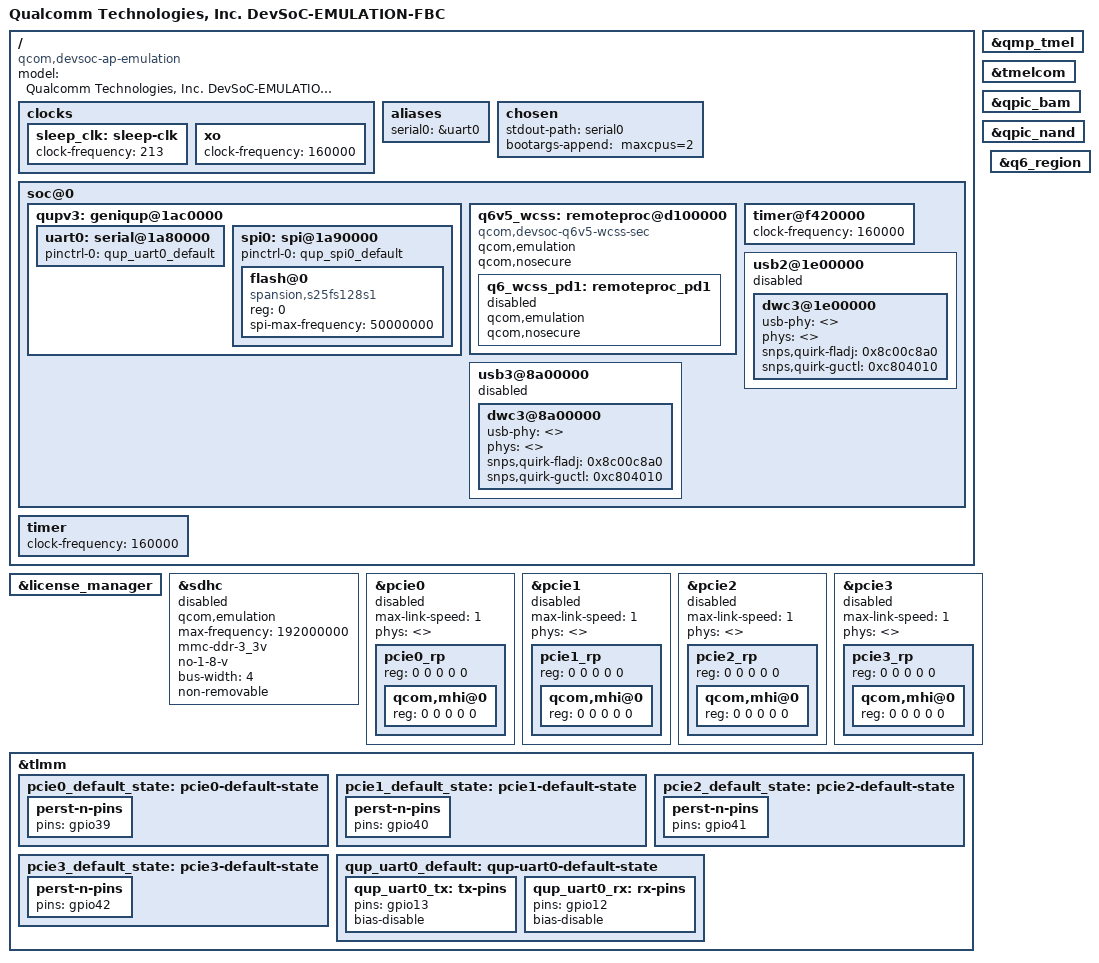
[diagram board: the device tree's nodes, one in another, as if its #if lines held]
// SPDX-License-Identifier: (GPL-2.0+ OR BSD-3-Clause)
/*
 * Dev SoC Emulation board device tree source
 *
 * Copyright (c) 2020-2021 The Linux Foundation. All rights reserved.
 * Copyright (c) 2022-2023 Qualcomm Innovation Center, Inc. All rights reserved.
 */

/dts-v1/;

#include "devsoc.dtsi"

/ {
	model = "Qualcomm Technologies, Inc. DevSoC-EMULATION-FBC";
	compatible = "qcom,devsoc-ap-emulation", "qcom,devsoc";

	/*Timer freq for rumi = timer freq / 150*/
	clocks {
		sleep_clk: sleep-clk {
			clock-frequency = <213>;
		};

		xo: xo {
			clock-frequency = <160000>;
		};
	};

	aliases {
		serial0 = &uart0;
	};

	chosen {
		stdout-path = "serial0";
		bootargs-append = " maxcpus=2";
	};

	soc@0 {
		qupv3: geniqup@1ac0000 {
			status = "okay";

			uart0: serial@1a80000 {
				pinctrl-0 = <&qup_uart0_default>;
				pinctrl-names = "default";
				status = "okay";
			};

			spi0: spi@1a90000 {
				pinctrl-0 = <&qup_spi0_default>;
				pinctrl-names = "default";
				status = "okay";

				flash@0 {
					compatible = "spansion,s25fs128s1", "jedec,spi-nor";
					#address-cells = <1>;
					#size-cells = <1>;
					reg = <0>;
					spi-max-frequency = <50000000>;
				};
			};
		};

		q6v5_wcss: remoteproc@d100000 {
			compatible = "qcom,devsoc-q6v5-wcss-sec";
			status = "okay";

#ifdef __QCOM_NON_SECURE_PIL__
			qcom,emulation;
			qcom,nosecure;
#endif
			q6_wcss_pd1: remoteproc_pd1 {
				status = "disabled";
#ifdef __QCOM_NON_SECURE_PIL__
				qcom,emulation;
				qcom,nosecure;
#endif
			};
		};

		/* Timer freq for rumi = timer freq / 150 */
		timer@f420000 {
			clock-frequency = <160000>;
		};

		usb2@1e00000 {
			status = "disabled";

			dwc3@1e00000 {
				usb-phy = <>;
				phys = <>;
				phy-names = "";
				snps,quirk-fladj = <0x8c00c8a0>;
				snps,quirk-guctl = <0xc804010>;
			};
		};

		usb3@8a00000 {
			status = "disabled";

			dwc3@8a00000 {
				usb-phy = <>;
				phys = <>;
				phy-names = "";
				snps,quirk-fladj = <0x8c00c8a0>;
				snps,quirk-guctl = <0xc804010>;
			};
		};
	};

	/* Timer freq for rumi = timer freq / 150 */
	timer {
		clock-frequency = <160000>;
	};
};

&license_manager {
	status = "okay";
};

&qmp_tmel {
	status = "okay";
};

&tmelcom {
	status = "okay";
};

&qpic_bam {
	status = "okay";
};

&qpic_nand {
	status = "okay";
};

&sdhc {
	qcom,emulation;
	/* over-ride the frequency to 48Mhz for emulation platform */
	max-frequency = <48000000>;
	/* Force 3.3V, because only that will support on emulation platform */
	mmc-ddr-3_3v;
	/* quirk to disable SDR104, SDR50 modes */
	no-1-8-v;
	max-frequency = <192000000>;
	bus-width = <4>;
	non-removable;
	status = "disabled";
};

&pcie0 {
	max-link-speed = <1>;
	phys = <>;
	phy-names = "";
	status = "disabled";

	pcie0_rp {
		reg = <0 0 0 0 0>;

		qcom,mhi@0 {
			reg = <0 0 0 0 0>;
		};
	};
};

&pcie1 {
	max-link-speed = <1>;
	phys = <>;
	phy-names = "";
	status = "disabled";

	pcie1_rp {
		reg = <0 0 0 0 0>;

		qcom,mhi@0 {
			reg = <0 0 0 0 0>;
		};
	};
};

&pcie2 {
	max-link-speed = <1>;
	phys = <>;
	phy-names = "";
	status = "disabled";

	pcie2_rp {
		reg = <0 0 0 0 0>;

		qcom,mhi@0 {
			reg = <0 0 0 0 0>;
		};
	};
};

&pcie3 {
	max-link-speed = <1>;
	phys = <>;
	phy-names = "";
	status = "disabled";

	pcie3_rp {
		reg = <0 0 0 0 0>;

		qcom,mhi@0 {
			reg = <0 0 0 0 0>;
		};
	};
};

&tlmm {
	pcie0_default_state: pcie0-default-state {
		perst-n-pins {
			pins = "gpio39";
		};
	};

	pcie1_default_state: pcie1-default-state {
		perst-n-pins {
			pins = "gpio40";
		};
	};

	pcie2_default_state: pcie2-default-state {
		perst-n-pins {
			pins = "gpio41";
		};
	};

	pcie3_default_state: pcie3-default-state {
		perst-n-pins {
			pins = "gpio42";
		};
	};

	qup_uart0_default: qup-uart0-default-state {
		qup_uart0_tx: tx-pins {
			pins = "gpio13";
			bias-disable;
		};

		qup_uart0_rx: rx-pins {
			pins = "gpio12";
			bias-disable;
		};
	};
};

&q6_region {
	status = "okay";
};
